AUTOSAR XML (schema 00047)
package /ASW_CORE0
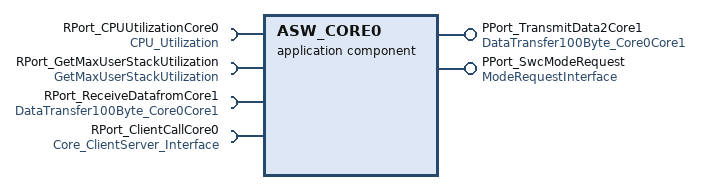
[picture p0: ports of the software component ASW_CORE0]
  application sw component type ASW_CORE0
    provide port PPort_TransmitData2Core1: provided-interface=DataTransfer100Byte_Core0Core1
    provide port PPort_SwcModeRequest: provided-interface=ModeRequestInterface
    4 x require port:
      RPort_CPUUtilizationCore0: required-interface=CPU_Utilization
      RPort_GetMaxUserStackUtilization: required-interface=GetMaxUserStackUtilization
      RPort_ReceiveDatafromCore1: required-interface=DataTransfer100Byte_Core0Core1
      RPort_ClientCallCore0: required-interface=Core_ClientServer_Interface
    behavior SwcInternalBehavior: data-type-mapping=AppMode_Mapping
      12 x timing event:
        TimingEvent_0: start-on-event=RE_CORE0_SWC_100ms, period=0.1
        TimingEvent_1: start-on-event=RE_CORE0_SWC_10ms, period=0.01
        TimingEvent_2: start-on-event=CCP_DaqListSetEvent0, period=0.001
        TimingEvent_3: start-on-event=CCP_DaqListSetEvent1, period=0.005
        TimingEvent_4: start-on-event=CCP_DaqListSetEvent2, period=0.01
        TimingEvent_5: start-on-event=MAIN_CORE0_1ms, period=0.001
        TimingEvent_6: start-on-event=MAIN_CORE0_2ms, period=0.002
        TimingEvent_7: start-on-event=MAIN_CORE0_5ms, period=0.005
        TimingEvent_8: start-on-event=MAIN_CORE0_10ms, period=0.01
        TimingEvent_9: start-on-event=RESBSL_CheckCalibChange, period=0.05
        TimingEvent_10: start-on-event=MAIN_CORE0_100ms, period=0.1
        TimingEvent_11: start-on-event=MAIN_CORE0_200ms, period=0.2
      explicit-inter-runnable-variables:
        data Explicit_IRV_1: type=Array100ByteDataElement
      13 x runnable:
        RE_CORE0_SWC_100ms: symbol=RE_CORE0_SWC_100ms_func
          data-receive-point-by-arguments:
            access DRPA_Data_ptr_0: accessed-variable=RPort_ReceiveDatafromCore1.Data_ptr
          data-send-points:
            access DSP_Data_ptr_0: accessed-variable=PPort_TransmitData2Core1.Data_ptr
          read-local-variables:
            access RLV_Explicit_IRV_1_0: accessed-variable=Explicit_IRV_1
          sync call SynchronousServerCallPoint: operation=RPort_CPUUtilizationCore0.CPU_Utilization
          sync call SynchronousServerCallPoint_0: operation=RPort_GetMaxUserStackUtilization.GetMaxUserStackUtilization
          sync call SynchronousServerCallPoint_1: operation=RPort_ClientCallCore0.Core_ClientServer
        RE_Core0FaultReaction: symbol=RE_Core0FaultReaction_func
          data-send-points:
            access DSP_AppMode_0: accessed-variable=PPort_SwcModeRequest.AppMode
        RE_CORE0_SWC_10ms: symbol=RE_CORE0_SWC_10ms_func
          written-local-variables:
            access WLV_Explicit_IRV_1_0: accessed-variable=Explicit_IRV_1
        CCP_DaqListSetEvent{0..2}: symbol=CCP_DaqListSetEvent{0..2}_func
        MAIN_CORE0_1ms: symbol=MAIN_CORE0_1ms_func
        MAIN_CORE0_2ms: symbol=MAIN_CORE0_2ms_func
        MAIN_CORE0_5ms: symbol=MAIN_CORE0_5ms_func
        MAIN_CORE0_10ms: symbol=MAIN_CORE0_10ms_func
        RESBSL_CheckCalibChange: symbol=RESBSL_CheckCalibChange_func
        MAIN_CORE0_100ms: symbol=MAIN_CORE0_100ms_func
        MAIN_CORE0_200ms: symbol=MAIN_CORE0_200ms_func
